# RockChip_RK3588 register map
Vendor: RockChip Electronics Co., Ltd.; Series: RK3588; File version: 0.1
Registers are 32-bit, read-write, no defined reset value unless marked. A register's access mark holds for its fields unless they carry their own. Offsets are from the block's base; [hi:lo] are bit positions; lines under a group give offsets from that group; {n}, {i} and the like mark numbered series; 'fields as' and 'values as' point back to an identical list.

## PMU (part 3 of 3)
Base 0xFD8D0000
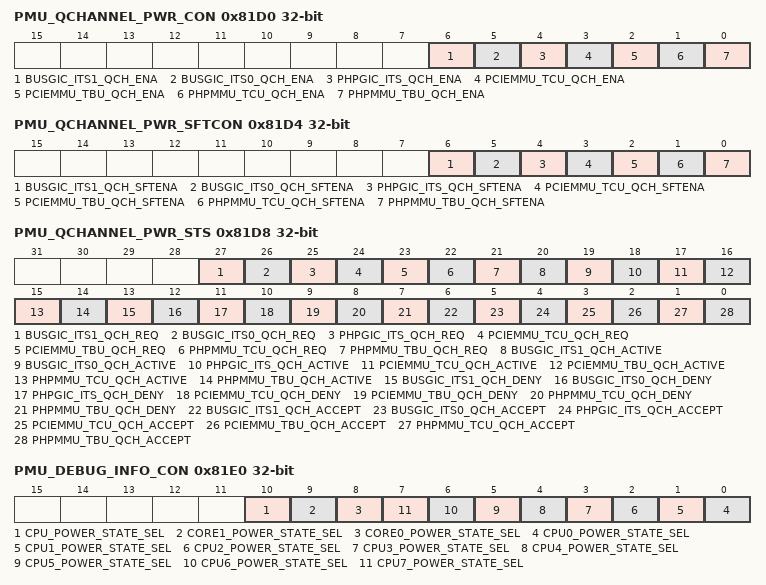
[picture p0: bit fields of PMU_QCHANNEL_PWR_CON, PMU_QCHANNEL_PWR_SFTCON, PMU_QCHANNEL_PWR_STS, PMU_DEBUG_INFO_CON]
0x81D0 PMU_QCHANNEL_PWR_CON — Q-Channel hardware power control register
  [all] fields
    0=DISABLE; 1=ENABLE
  [6] BUSGIC_ITS1_QCH_ENA — Enable BUSGIC-ITS1 Q-Channel power control by hardware.
  [5] BUSGIC_ITS0_QCH_ENA — Enable BUSGIC-ITS0 Q-Channel power control by hardware.
  [4] PHPGIC_ITS_QCH_ENA — Enable PHPGIC-ITS Q-Channel power control by hardware.
  [3] PCIEMMU_TCU_QCH_ENA — Enable PCIEMMU-TCU Q-Channel power control by hardware.
  [2] PCIEMMU_TBU_QCH_ENA — Enable PCIEMMU-TBU Q-Channel power control by hardware.
  [1] PHPMMU_TCU_QCH_ENA — Enable PHPMMU-TCU Q-Channel power control by hardware.
  [0] PHPMMU_TBU_QCH_ENA — Enable PHPMMU-TBU Q-Channel power control by hardware.
0x81D4 PMU_QCHANNEL_PWR_SFTCON — Q-Channel software power control register
  [all] fields
    0=DISABLE; 1=ENABLE
  [6] BUSGIC_ITS1_QCH_SFTENA — Enable BUSGIC-ITS1 Q-Channel power control by software.
  [5] BUSGIC_ITS0_QCH_SFTENA — Enable BUSGIC-ITS0 Q-Channel power control by software.
  [4] PHPGIC_ITS_QCH_SFTENA — Enable PHPGIC-ITS Q-Channel power control by software.
  [3] PCIEMMU_TCU_QCH_SFTENA — Enable PCIEMMU-TCU Q-Channel power control by software.
  [2] PCIEMMU_TBU_QCH_SFTENA — Enable PCIEMMU-TBU Q-Channel power control by software.
  [1] PHPMMU_TCU_QCH_SFTENA — Enable PHPMMU-TCU Q-Channel power control by software.
  [0] PHPMMU_TBU_QCH_SFTENA — Enable PHPMMU-TBU Q-Channel power control by software.
0x81D8 PMU_QCHANNEL_PWR_STS — Q-Channel power status register
  [27] BUSGIC_ITS1_QCH_REQ ro — Request status for BUSGIC-ITS1 Q-Channel power control.
    0=NOT_VALID; 1=VALID
  [26] BUSGIC_ITS0_QCH_REQ ro — Request status for BUSGIC-ITS0 Q-Channel power control.
    0=NOT_VALID; 1=VALID
  [25] PHPGIC_ITS_QCH_REQ ro — Request status for PHPGIC-ITS Q-Channel power control.
    0=NOT_VALID; 1=VALID
  [24] PCIEMMU_TCU_QCH_REQ ro — Request status for PCIEMMU-TCU Q-Channel power control.
    0=NOT_VALID; 1=VALID
  [23] PCIEMMU_TBU_QCH_REQ ro — Request status for PCIEMMU-TBU Q-Channel power control.
    0=NOT_VALID; 1=VALID
  [22] PHPMMU_TCU_QCH_REQ ro — Request status for PHPMMU-TCU Q-Channel power control.
    0=NOT_VALID; 1=VALID
  [21] PHPMMU_TBU_QCH_REQ ro — Request status for PHPMMU-TBU Q-Channel power control.
    0=NOT_VALID; 1=VALID
  [20] BUSGIC_ITS1_QCH_ACTIVE ro — Active status for PHPBUS-ITS1 Q-Channel power control.
    0=INACTIVE; 1=ACTIVE
  [19] BUSGIC_ITS0_QCH_ACTIVE ro — Active status for PHPBUS-ITS0 Q-Channel power control.
    0=INACTIVE; 1=ACTIVE
  [18] PHPGIC_ITS_QCH_ACTIVE ro — Active status for PHPGIC-ITS Q-Channel power control.
    0=INACTIVE; 1=ACTIVE
  [17] PCIEMMU_TCU_QCH_ACTIVE ro — Active status for PCIEMMU-TCU Q-Channel power control.
    0=INACTIVE; 1=ACTIVE
  [16] PCIEMMU_TBU_QCH_ACTIVE ro — Active status for PCIEMMU-TBU Q-Channel power control.
    0=INACTIVE; 1=ACTIVE
  [15] PHPMMU_TCU_QCH_ACTIVE ro — Active status for PHPMMU-TCU Q-Channel power control.
    0=INACTIVE; 1=ACTIVE
  [14] PHPMMU_TBU_QCH_ACTIVE ro — Active status for PHPMMU-TBU Q-Channel power control.
    0=INACTIVE; 1=ACTIVE
  [13] BUSGIC_ITS1_QCH_DENY ro — Deny status for PBUSGIC-ITS1 Q-Channel power control.
    0=NOT_DENY; 1=DENY
  [12] BUSGIC_ITS0_QCH_DENY ro — Deny status for BUSGIC-ITS0 Q-Channel power control.
    0=NOT_DENY; 1=DENY
  [11] PHPGIC_ITS_QCH_DENY ro — Deny status for PHPGIC-ITS Q-Channel power control.
    0=NOT_DENY; 1=DENY
  [10] PCIEMMU_TCU_QCH_DENY ro — Deny status for PCIEMMU-TCU Q-Channel power control.
    0=NOT_DENY; 1=DENY
  [9] PCIEMMU_TBU_QCH_DENY ro — Deny status for PCIEMMU-TBU Q-Channel power control.
    0=NOT_DENY; 1=DENY
  [8] PHPMMU_TCU_QCH_DENY ro — Deny status for PHPMMU-TCU Q-Channel power control.
    0=NOT_DENY; 1=DENY
  [7] PHPMMU_TBU_QCH_DENY ro — Deny status for PHPMMU-TBU Q-Channel power control.
    0=NOT_DENY; 1=DENY
  [6] BUSGIC_ITS1_QCH_ACCEPT ro — Accept status for BUSGIC-ITS1 Q-Channel power control.
    0=NOT ACCEPT; 1=ACCEPT
  [5] BUSGIC_ITS0_QCH_ACCEPT ro — Accept status for BUSGIC-ITS0 Q-Channel power control.
    0=NOT ACCEPT; 1=ACCEPT
  [4] PHPGIC_ITS_QCH_ACCEPT ro — Accept status for PHPGIC-ITS Q-Channel power control.
    0=NOT ACCEPT; 1=ACCEPT
  [3] PCIEMMU_TCU_QCH_ACCEPT ro — Accept status for PCIEMMU-TCU Q-Channel power control.
    0=NOT ACCEPT; 1=ACCEPT
  [2] PCIEMMU_TBU_QCH_ACCEPT ro — Accept status for PCIEMMU-TBU Q-Channel power control.
    0=NOT ACCEPT; 1=ACCEPT
  [1] PHPMMU_TCU_QCH_ACCEPT ro — Accept status for PHPMMU-TCU Q-Channel power control.
    0=NOT ACCEPT; 1=ACCEPT
  [0] PHPMMU_TBU_QCH_ACCEPT ro — Accept status for PHPMMU-TBU Q-Channel power control.
    0=NOT ACCEPT; 1=ACCEPT
0x81E0 PMU_DEBUG_INFO_CON — PMU debug information control register
  [all] fields
    0=NOT_SELECT; 1=SELECT
  [10] CPU_POWER_STATE_SEL — Select CPU power state as debug information output to IO.
  [9] CORE1_POWER_STATE_SEL — Select BIGCORE1 power state as debug information output to IO.
  [8] CORE0_POWER_STATE_SEL — Select BIGCORE0 power state as debug information output to IO.
  [n] CPU{n}_POWER_STATE_SEL (n=0..7) — Select CPU{n} power state as CPU power state.
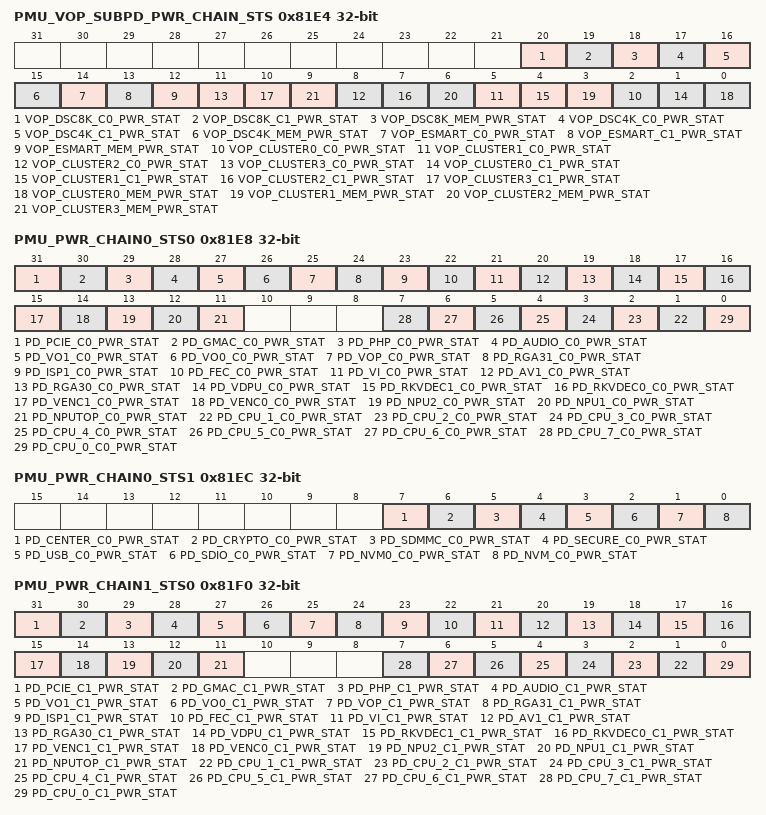
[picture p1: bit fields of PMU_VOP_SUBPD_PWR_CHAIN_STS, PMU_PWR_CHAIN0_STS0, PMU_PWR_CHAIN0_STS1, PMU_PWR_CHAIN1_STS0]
0x81E4 PMU_VOP_SUBPD_PWR_CHAIN_STS — VOP sub-domain power chain status register
  [20] VOP_DSC8K_C0_PWR_STAT ro — PD_VOPDSC8K power chain 0 power state.
    0=POWER_DOWN; 1=POWER_UP
  [19] VOP_DSC8K_C1_PWR_STAT ro — PD_VOPDSC8K power chain 1 power state.
    0=POWER_DOWN; 1=POWER_UP
  [18] VOP_DSC8K_MEM_PWR_STAT ro — PD_VOPDSC8K memory power state.
    0=POWER_UP; 1=POWER_DOWN
  [17] VOP_DSC4K_C0_PWR_STAT ro — PD_VOPDSC4K power chain 0 power state.
    0=POWER_DOWN; 1=POWER_UP
  [16] VOP_DSC4K_C1_PWR_STAT ro — PD_VOPDSC4K power chain 1 power state.
    0=POWER_DOWN; 1=POWER_UP
  [15] VOP_DSC4K_MEM_PWR_STAT ro — PD_VOPDSC4K memory power state.
    0=POWER_UP; 1=POWER_DOWN
  [14] VOP_ESMART_C0_PWR_STAT ro — PD_VOPESMART power chain 0 power state.
    0=POWER_DOWN; 1=POWER_UP
  [13] VOP_ESMART_C1_PWR_STAT ro — PD_VOPESMART power chain 1 power state.
    0=POWER_DOWN; 1=POWER_UP
  [12] VOP_ESMART_MEM_PWR_STAT ro — PD_VOPESMART memory power state.
    0=POWER_UP; 1=POWER_DOWN
  [3n+2] VOP_CLUSTER{n}_C0_PWR_STAT ro (n=0..3) — PD_VOPCLUSTER{n} power chain 0 power state.
    0=POWER_DOWN; 1=POWER_UP
  [3n+1] VOP_CLUSTER{n}_C1_PWR_STAT ro (n=0..3) — PD_VOPCLUSTER{n} power chain 1 power state.
    0=POWER_DOWN; 1=POWER_UP
  [3n] VOP_CLUSTER{n}_MEM_PWR_STAT ro (n=0..3) — PD_VOPCLUSTER{n} memory power state.
    0=POWER_UP; 1=POWER_DOWN
0x81E8 PMU_PWR_CHAIN0_STS0 — Power domain power chain 0 status register 0
  [31] PD_PCIE_C0_PWR_STAT ro — The power state of PD_PCIE power chain 0.
    0=POWER_DOWN; 1=POWER_UP
  [30] PD_GMAC_C0_PWR_STAT ro — The power state of PD_GMAC power chain 0.
    0=POWER_DOWN; 1=POWER_UP
  [29] PD_PHP_C0_PWR_STAT ro — The power state of PD_PHP power chain 0.
    0=POWER_DOWN; 1=POWER_UP
  [28] PD_AUDIO_C0_PWR_STAT ro — The power state of PD_AUDIO power chain 0.
    0=POWER_DOWN; 1=POWER_UP
  [27] PD_VO1_C0_PWR_STAT ro — The power state of PD_VO1 power chain 0.
    0=POWER_DOWN; 1=POWER_UP
  [26] PD_VO0_C0_PWR_STAT ro — The power state of PD_VO0 power chain 0.
    0=POWER_DOWN; 1=POWER_UP
  [25] PD_VOP_C0_PWR_STAT ro — The power state of PD_VOP power chain 0.
    0=POWER_DOWN; 1=POWER_UP
  [24] PD_RGA31_C0_PWR_STAT ro — The power state of PD_RGA31 power chain 0.
    0=POWER_DOWN; 1=POWER_UP
  [23] PD_ISP1_C0_PWR_STAT ro — The power state of PD_ISP1 power chain 0.
    0=POWER_DOWN; 1=POWER_UP
  [22] PD_FEC_C0_PWR_STAT ro — The power state of PD_FEC power chain 0.
    0=POWER_DOWN; 1=POWER_UP
  [21] PD_VI_C0_PWR_STAT ro — The power state of PD_VI power chain 0.
    0=POWER_DOWN; 1=POWER_UP
  [20] PD_AV1_C0_PWR_STAT ro — The power state of PD_AV1 power chain 0.
    0=POWER_DOWN; 1=POWER_UP
  [19] PD_RGA30_C0_PWR_STAT ro — The power state of PD_RGA30.
    0=POWER_DOWN; 1=POWER_UP
  [18] PD_VDPU_C0_PWR_STAT ro — The power state of PD_VDPU power chain 0.
    0=POWER_DOWN; 1=POWER_UP
  [17] PD_RKVDEC1_C0_PWR_STAT ro — The power state of PD_RKVDEC1 power chain 0.
    0=POWER_DOWN; 1=POWER_UP
  [16] PD_RKVDEC0_C0_PWR_STAT ro — The power state of PD_RKVDEC0 power chain 0.
    0=POWER_DOWN; 1=POWER_UP
  [15] PD_VENC1_C0_PWR_STAT ro — The power state of PD_VENC1 power chain 0.
    0=POWER_DOWN; 1=POWER_UP
  [14] PD_VENC0_C0_PWR_STAT ro — The power state of PD_VENC0 power chain 0.
    0=POWER_DOWN; 1=POWER_UP
  [13] PD_NPU2_C0_PWR_STAT ro — The power state of PD_NPU2 power chain 0.
    0=POWER_DOWN; 1=POWER_UP
  [12] PD_NPU1_C0_PWR_STAT ro — The power state of PD_NPU1 power chain 0.
    0=POWER_DOWN; 1=POWER_UP
  [11] PD_NPUTOP_C0_PWR_STAT ro — The power state of PD_NPUTOP power chain 0.
    0=POWER_DOWN; 1=POWER_UP
  [n] PD_CPU_{n}_C0_PWR_STAT ro (n=1..7) — The power state of PD_CPU_{n} power chain 0.
    0=POWER_DOWN; 1=POWER_UP
  [0] PD_CPU_0_C0_PWR_STAT ro — The power state of PD_CPU_0 power chain 0.
    0=POWER_DOWN; 1=POWER UP
0x81EC PMU_PWR_CHAIN0_STS1 — Power domain power chain 0 status register 1
  [7] PD_CENTER_C0_PWR_STAT ro — The power state of PD_CENTER power chain 0.
    0=POWER_DOWN; 1=POWER_UP
  [6] PD_CRYPTO_C0_PWR_STAT ro — The power state of PD_CRYPTO power chain 0.
    0=POWER_DOWN; 1=POWER_UP
  [5] PD_SDMMC_C0_PWR_STAT ro — The power state of PD_SDMMC power chain 0.
    0=POWER_DOWN; 1=POWER_UP
  [4] PD_SECURE_C0_PWR_STAT ro — The power state of PD_SECURE power chain 0.
    0=POWER_DOWN; 1=POWER_UP
  [3] PD_USB_C0_PWR_STAT ro — The power state of PD_USB power chain 0.
    0=POWER_DOWN; 1=POWER_UP
  [2] PD_SDIO_C0_PWR_STAT ro — The power state of PD_SDIO power chain 0.
    0=POWER_DOWN; 1=POWER_UP
  [1] PD_NVM0_C0_PWR_STAT ro — The power state of PD_NVM0 power chain 0.
    0=POWER_DOWN; 1=POWER_UP
  [0] PD_NVM_C0_PWR_STAT ro — The power state of PD_NVM power chain 0.
    0=POWER_DOWN; 1=POWER UP
0x81F0 PMU_PWR_CHAIN1_STS0 — Power domain power chain 1 status register 0
  [31] PD_PCIE_C1_PWR_STAT ro — The power state of PD_PCIE power chain 1.
    0=POWER_DOWN; 1=POWER_UP
  [30] PD_GMAC_C1_PWR_STAT ro — The power state of PD_GMAC power chain 1.
    0=POWER_DOWN; 1=POWER_UP
  [29] PD_PHP_C1_PWR_STAT ro — The power state of PD_PHP power chain 1.
    0=POWER_DOWN; 1=POWER_UP
  [28] PD_AUDIO_C1_PWR_STAT ro — The power state of PD_AUDIO power chain 1.
    0=POWER_DOWN; 1=POWER_UP
  [27] PD_VO1_C1_PWR_STAT ro — The power state of PD_VO1 power chain 1.
    0=POWER_DOWN; 1=POWER_UP
  [26] PD_VO0_C1_PWR_STAT ro — The power state of PD_VO0 power chain 1.
    0=POWER_DOWN; 1=POWER_UP
  [25] PD_VOP_C1_PWR_STAT ro — The power state of PD_VOP power chain 1.
    0=POWER_DOWN; 1=POWER_UP
  [24] PD_RGA31_C1_PWR_STAT ro — The power state of PD_RGA31 power chain 1.
    0=POWER_DOWN; 1=POWER_UP
  [23] PD_ISP1_C1_PWR_STAT ro — The power state of PD_ISP1 power chain 1.
    0=POWER_DOWN; 1=POWER_UP
  [22] PD_FEC_C1_PWR_STAT ro — The power state of PD_FEC power chain 1.
    0=POWER_DOWN; 1=POWER_UP
  [21] PD_VI_C1_PWR_STAT ro — The power state of PD_VI power chain 1.
    0=POWER_DOWN; 1=POWER_UP
  [20] PD_AV1_C1_PWR_STAT ro — The power state of PD_AV1 power chain 1.
    0=POWER_DOWN; 1=POWER_UP
  [19] PD_RGA30_C1_PWR_STAT ro — The power state of PD_RGA30.
    0=POWER_DOWN; 1=POWER_UP
  [18] PD_VDPU_C1_PWR_STAT ro — The power state of PD_VDPU power chain 1.
    0=POWER_DOWN; 1=POWER_UP
  [17] PD_RKVDEC1_C1_PWR_STAT ro — The power state of PD_RKVDEC1 power chain 1.
    0=POWER_DOWN; 1=POWER_UP
  [16] PD_RKVDEC0_C1_PWR_STAT ro — The power state of PD_RKVDEC0 power chain 1.
    0=POWER_DOWN; 1=POWER_UP
  [15] PD_VENC1_C1_PWR_STAT ro — The power state of PD_VENC1 power chain 1.
    0=POWER_DOWN; 1=POWER_UP
  [14] PD_VENC0_C1_PWR_STAT ro — The power state of PD_VENC0 power chain 1.
    0=POWER_DOWN; 1=POWER_UP
  [13] PD_NPU2_C1_PWR_STAT ro — The power state of PD_NPU2 power chain 1.
    0=POWER_DOWN; 1=POWER_UP
  [12] PD_NPU1_C1_PWR_STAT ro — The power state of PD_NPU1 power chain 1.
    0=POWER_DOWN; 1=POWER_UP
  [11] PD_NPUTOP_C1_PWR_STAT ro — The power state of PD_NPUTOP power chain 1.
    0=POWER_DOWN; 1=POWER_UP
  [n] PD_CPU_{n}_C1_PWR_STAT ro (n=1..7) — The power state of PD_CPU_{n} power chain 1.
    0=POWER_DOWN; 1=POWER_UP
  [0] PD_CPU_0_C1_PWR_STAT ro — The power state of PD_CPU_0 power chain 1.
    0=POWER_DOWN; 1=POWER UP
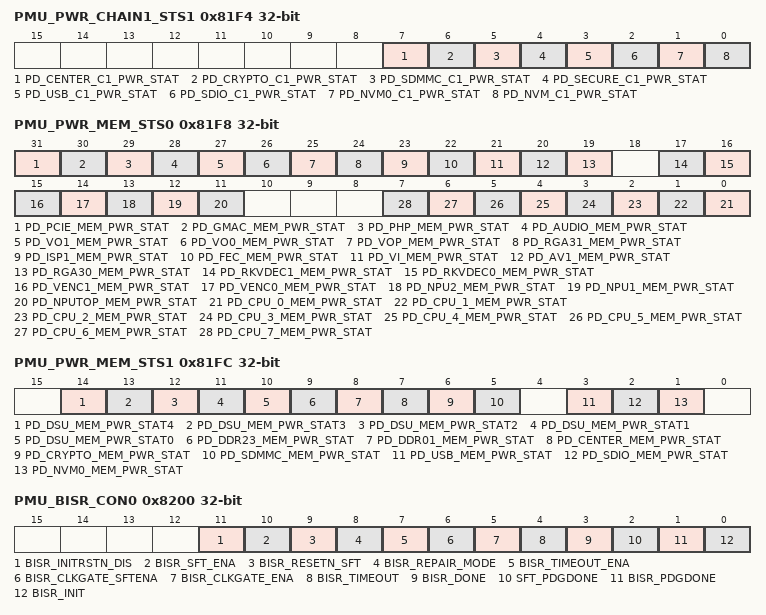
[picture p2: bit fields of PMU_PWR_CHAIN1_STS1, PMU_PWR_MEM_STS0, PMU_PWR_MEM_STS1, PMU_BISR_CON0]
0x81F4 PMU_PWR_CHAIN1_STS1 — Power domain power chain 1 status register 1
  [7] PD_CENTER_C1_PWR_STAT ro — The power state of PD_CENTER power chain 1.
    0=POWER_DOWN; 1=POWER_UP
  [6] PD_CRYPTO_C1_PWR_STAT ro — The power state of PD_CRYPTO power chain 1.
    0=POWER_DOWN; 1=POWER_UP
  [5] PD_SDMMC_C1_PWR_STAT ro — The power state of PD_SDMMC power chain 1.
    0=POWER_DOWN; 1=POWER_UP
  [4] PD_SECURE_C1_PWR_STAT ro — The power state of PD_SECURE power chain 1.
    0=POWER_DOWN; 1=POWER_UP
  [3] PD_USB_C1_PWR_STAT ro — The power state of PD_USB power chain 1.
    0=POWER_DOWN; 1=POWER_UP
  [2] PD_SDIO_C1_PWR_STAT ro — The power state of PD_SDIO power chain 1.
    0=POWER_DOWN; 1=POWER_UP
  [1] PD_NVM0_C1_PWR_STAT ro — The power state of PD_NVM0 power chain 1.
    0=POWER_DOWN; 1=POWER_UP
  [0] PD_NVM_C1_PWR_STAT ro — The power state of PD_NVM power chain 1.
    0=POWER_DOWN; 1=POWER UP
0x81F8 PMU_PWR_MEM_STS0 — Power domain memory power status register 0
  [all] fields
    0=POWER_UP; 1=POWER_DOWN
  [31] PD_PCIE_MEM_PWR_STAT ro — The power state of PD_PCIE memory.
  [30] PD_GMAC_MEM_PWR_STAT ro — The power state of PD_GMAC memory.
  [29] PD_PHP_MEM_PWR_STAT ro — The power state of PD_PHP memory.
  [28] PD_AUDIO_MEM_PWR_STAT ro — The power state of PD_AUDIO memory.
  [27] PD_VO1_MEM_PWR_STAT ro — The power state of PD_VO1 memory.
  [26] PD_VO0_MEM_PWR_STAT ro — The power state of PD_VO0 memory.
  [25] PD_VOP_MEM_PWR_STAT ro — The power state of PD_VOP memory.
  [24] PD_RGA31_MEM_PWR_STAT ro — The power state of PD_RGA31 memory.
  [23] PD_ISP1_MEM_PWR_STAT ro — The power state of PD_ISP1 memory.
  [22] PD_FEC_MEM_PWR_STAT ro — The power state of PD_FEC memory.
  [21] PD_VI_MEM_PWR_STAT ro — The power state of PD_VI memory.
  [20] PD_AV1_MEM_PWR_STAT ro — The power state of PD_AV1 memory.
  [19] PD_RGA30_MEM_PWR_STAT ro — The power state of PD_RGA30 memory.
  [17] PD_RKVDEC1_MEM_PWR_STAT ro — The power state of PD_RKVDEC1 memory.
  [16] PD_RKVDEC0_MEM_PWR_STAT ro — The power state of PD_RKVDEC0 memory.
  [15] PD_VENC1_MEM_PWR_STAT ro — The power state of PD_VENC1 memory.
  [14] PD_VENC0_MEM_PWR_STAT ro — The power state of PD_VENC0 memory.
  [13] PD_NPU2_MEM_PWR_STAT ro — The power state of PD_NPU2 memory.
  [12] PD_NPU1_MEM_PWR_STAT ro — The power state of PD_NPU1 memory.
  [11] PD_NPUTOP_MEM_PWR_STAT ro — The power state of PD_NPUTOP memory.
  [n] PD_CPU_{n}_MEM_PWR_STAT ro (n=0..7) — The power state of PD_CPU_{n} memory.
0x81FC PMU_PWR_MEM_STS1 — Power domain memory power status register 1
  [all] fields
    0=POWER_UP; 1=POWER_DOWN
  [14] PD_DSU_MEM_PWR_STAT4 ro — used to indicate other memory power state.
  [13] PD_DSU_MEM_PWR_STAT3 ro — used to indicate "L3 Tag ways 8~11, L3 Data portion 1 RAMs" memory power state.
  [12] PD_DSU_MEM_PWR_STAT2 ro — used to indicate "L3 Tag ways 4~7" memory power state.
  [11] PD_DSU_MEM_PWR_STAT1 ro — used to indicate "L3 Tag ways 0~3, L3 Data portion 0, and L3 Victim RAMs" memory state.
  [10] PD_DSU_MEM_PWR_STAT0 ro — used to indicate "Snoop filter and LTDB RAMs" memory power state.
  [9] PD_DDR23_MEM_PWR_STAT ro — The power state of VD_DDR23 memory.
  [8] PD_DDR01_MEM_PWR_STAT ro — The power state of VD_DDR01 memory.
  [7] PD_CENTER_MEM_PWR_STAT ro — The power state of PD_CENTER memory.
  [6] PD_CRYPTO_MEM_PWR_STAT ro — The power state of PD_CRYPTO memory.
  [5] PD_SDMMC_MEM_PWR_STAT ro — The power state of PD_SDMMC memory.
  [3] PD_USB_MEM_PWR_STAT ro — The power state of PD_USB memory.
  [2] PD_SDIO_MEM_PWR_STAT ro — The power state of PD_SDIO memory.
  [1] PD_NVM0_MEM_PWR_STAT ro — The power state of PD_NVM0 memory.
0x8200 PMU_BISR_CON0 — Memory repair control register 0
  [11] BISR_INITRSTN_DIS — Disable initial reset for memory repair logic.
    0=ENABLE; 1=DISABLE
  [10] BISR_SFT_ENA — Enable memory repair control by software.
    0=DISABLE; 1=ENABLE
  [9] BISR_RESETN_SFT — Generate bisr_resetN by software.
  [8] BISR_REPAIR_MODE — Memory repair mode.
    0=SERIAL (Serial repair mode. In this mode, memory repair will start after power domain is power up, not need to wait for other domain power up. If multi domains are power up at the same time, the repair is executed according to the repair group order.); 1=PARALLEL (Parallel repair mode. In this mode, memory repair will not start until all specified power domains are power up.)
  [7] BISR_TIMEOUT_ENA — Enable memory repair timeout counter.
    0=DISABLE; 1=ENABLE
  [6] BISR_CLKGATE_SFTENA — Enable memory repair clock gating by software. If asserted, memory repair clock is gated.
    0=DISABLE; 1=ENABLE
  [5] BISR_CLKGATE_ENA — Enable memory repair auto clock gating by hardware. If asserted, memory repair clock is auto gated when memory repair is idle.
    0=DISABLE; 1=ENABLE
  [4] BISR_TIMEOUT — PDGDone come from bisr_timeout, controlled by hardware. Only one bit can be set to 1 at a time.
  [3] BISR_DONE — PDGDone come from bisr_Done, controlled by hardware. Only one bit can be set to 1 at a time.
  [2] SFT_PDGDONE — PDGDone come from sft_PDGDone (pd_xx_pdgdone_sftena), controlled by software. Only one bit can be set to 1 at a time.
  [1] BISR_PDGDONE — PDGDone come from bisr_PDGDone, controlled by hardware. Only one bit can be set to 1 at a time.
  [0] BISR_INIT — Enable memory repair initialization. When asserted, the chip will startup memory repair for memory of power on if external memory repair information is ready. It should be set to 0 if chip is reset by software.
    0=DISABLE; 1=ENABLE
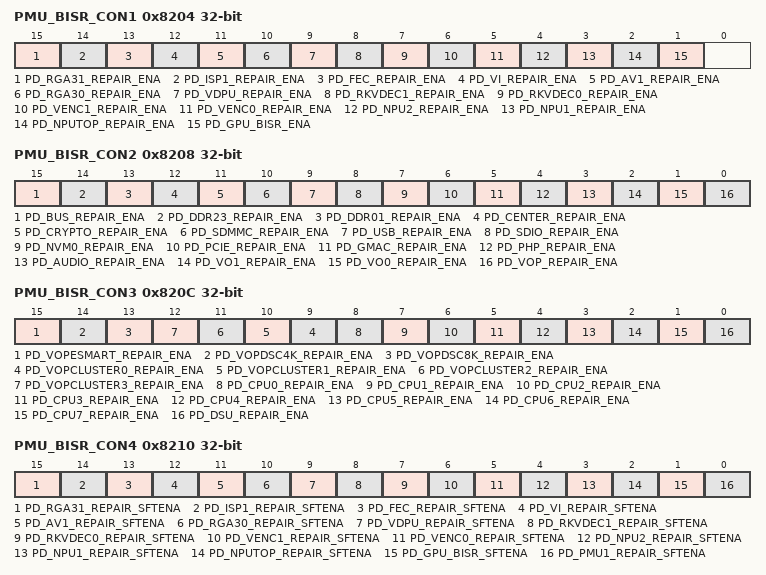
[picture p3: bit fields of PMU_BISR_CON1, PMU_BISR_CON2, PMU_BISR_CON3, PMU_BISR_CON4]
0x8204 PMU_BISR_CON1 — Memory repair control register 1
  [all] fields
    0=DISABLE; 1=ENABLE
  [15] PD_RGA31_REPAIR_ENA — Enable memory repair for PD_RGA31 by hardware.
  [14] PD_ISP1_REPAIR_ENA — Enable memory repair for PD_ISP1 by hardware.
  [13] PD_FEC_REPAIR_ENA — Enable memory repair for PD_FEC by hardware.
  [12] PD_VI_REPAIR_ENA — Enable memory repair for PD_VI by hardware.
  [11] PD_AV1_REPAIR_ENA — Enable memory repair for PD_AV1 by hardware.
  [10] PD_RGA30_REPAIR_ENA — Enable memory repair for PD_RGA30 by hardware.
  [9] PD_VDPU_REPAIR_ENA — Enable memory repair for PD_VDPU by hardware.
  [8] PD_RKVDEC1_REPAIR_ENA — Enable memory repair for PD_RKVDEC1 by hardware.
  [7] PD_RKVDEC0_REPAIR_ENA — Enable memory repair for PD_RKVDEC0 by hardware.
  [6] PD_VENC1_REPAIR_ENA — Enable memory repair for PD_VENC1 by hardware.
  [5] PD_VENC0_REPAIR_ENA — Enable memory repair for PD_VENC0 by hardware.
  [4] PD_NPU2_REPAIR_ENA — Enable memory repair for PD_NPU2 by hardware.
  [3] PD_NPU1_REPAIR_ENA — Enable memory repair for PD_NPU1 by hardware.
  [2] PD_NPUTOP_REPAIR_ENA — Enable memory repair for PD_NPUTOP by hardware.
  [1] PD_GPU_BISR_ENA — Enable memory repair for VD_GPU by hardware.
0x8208 PMU_BISR_CON2 — Memory repair control register 2
  [all] fields
    0=DISABLE; 1=ENABLE
  [15] PD_BUS_REPAIR_ENA — Enable memory repair for PD_BUS by hardware.
  [14] PD_DDR23_REPAIR_ENA — Enable memory repair for VD_DDR23 by hardware.
  [13] PD_DDR01_REPAIR_ENA — Enable memory repair for VD_DDR01 by hardware.
  [12] PD_CENTER_REPAIR_ENA — Enable memory repair for PD_CENTER by hardware.
  [11] PD_CRYPTO_REPAIR_ENA — Enable memory repair for PD_CRYPTO by hardware.
  [10] PD_SDMMC_REPAIR_ENA — Enable memory repair for PD_SDMMC by hardware.
  [9] PD_USB_REPAIR_ENA — Enable memory repair for PD_USB by hardware.
  [8] PD_SDIO_REPAIR_ENA — Enable memory repair for PD_SDIO by hardware.
  [7] PD_NVM0_REPAIR_ENA — Enable memory repair for PD_NVM0 by hardware.
  [6] PD_PCIE_REPAIR_ENA — Enable memory repair for PD_PCIE by hardware.
  [5] PD_GMAC_REPAIR_ENA — Enable memory repair for PD_GMAC by hardware.
  [4] PD_PHP_REPAIR_ENA — Enable memory repair for PD_PHP by hardware.
  [3] PD_AUDIO_REPAIR_ENA — Enable memory repair for PD_AUDIO by hardware.
  [2] PD_VO1_REPAIR_ENA — Enable memory repair for PD_VO1 by hardware.
  [1] PD_VO0_REPAIR_ENA — Enable memory repair for PD_VO0 by hardware.
  [0] PD_VOP_REPAIR_ENA — Enable memory repair for PD_VOP by hardware.
0x820C PMU_BISR_CON3 — Memory repair control register 3
  [all] fields
    0=DISABLE; 1=ENABLE
  [15] PD_VOPESMART_REPAIR_ENA — Enable memory repair for PD_VOPESMART by hardware.
  [14] PD_VOPDSC4K_REPAIR_ENA — Enable memory repair for PD_VOPDSC4K by hardware.
  [13] PD_VOPDSC8K_REPAIR_ENA — Enable memory repair for PD_VOPDSC8K by hardware.
  [n+9] PD_VOPCLUSTER{n}_REPAIR_ENA (n=0..3) — Enable memory repair for PD_VOPCLUSTER{n} by hardware.
  [8-n] PD_CPU{n}_REPAIR_ENA (n=0..7) — Enable memory repair for PD_CPU{n} by hardware.
  [0] PD_DSU_REPAIR_ENA — Enable memory repair for PD_DSU by hardware.
0x8210 PMU_BISR_CON4 — Memory repair control register 4
  [all] fields
    0=DISABLE; 1=ENABLE
  [15] PD_RGA31_REPAIR_SFTENA — Enable memory repair for PD_RGA31 by software.
  [14] PD_ISP1_REPAIR_SFTENA — Enable memory repair for PD_ISP1 by software.
  [13] PD_FEC_REPAIR_SFTENA — Enable memory repair for PD_FEC by software.
  [12] PD_VI_REPAIR_SFTENA — Enable memory repair for PD_VI by software.
  [11] PD_AV1_REPAIR_SFTENA — Enable memory repair for PD_AV1 by software.
  [10] PD_RGA30_REPAIR_SFTENA — Enable memory repair for PD_RGA30 by software.
  [9] PD_VDPU_REPAIR_SFTENA — Enable memory repair for PD_VDPU by software.
  [8] PD_RKVDEC1_REPAIR_SFTENA — Enable memory repair for PD_RKVDEC1 by software.
  [7] PD_RKVDEC0_REPAIR_SFTENA — Enable memory repair for PD_RKVDEC0 by software.
  [6] PD_VENC1_REPAIR_SFTENA — Enable memory repair for PD_VENC1 by software.
  [5] PD_VENC0_REPAIR_SFTENA — Enable memory repair for PD_VENC0 by software.
  [4] PD_NPU2_REPAIR_SFTENA — Enable memory repair for PD_NPU2 by software.
  [3] PD_NPU1_REPAIR_SFTENA — Enable memory repair for PD_NPU1 by software.
  [2] PD_NPUTOP_REPAIR_SFTENA — Enable memory repair for PD_NPUTOP by software.
  [1] PD_GPU_BISR_SFTENA — Enable memory repair for VD_GPU by software.
  [0] PD_PMU1_REPAIR_SFTENA — Enable memory repair for PD_PMU1 by software.
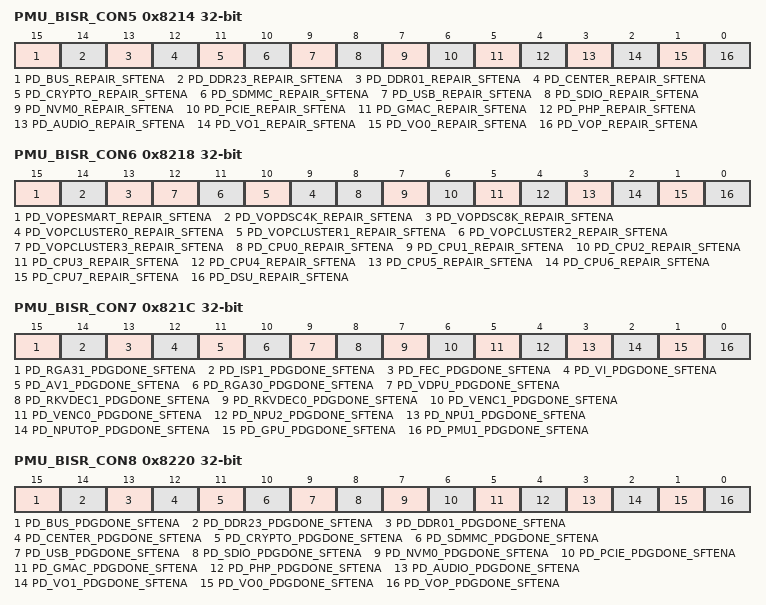
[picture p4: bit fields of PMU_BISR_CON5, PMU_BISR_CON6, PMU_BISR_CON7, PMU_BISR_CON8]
0x8214 PMU_BISR_CON5 — Memory repair control register 5
  [all] fields
    0=DISABLE; 1=ENABLE
  [15] PD_BUS_REPAIR_SFTENA — Enable memory repair for PD_BUS by software.
  [14] PD_DDR23_REPAIR_SFTENA — Enable memory repair for VD_DDR23 by software.
  [13] PD_DDR01_REPAIR_SFTENA — Enable memory repair for VD_DDR01 by software.
  [12] PD_CENTER_REPAIR_SFTENA — Enable memory repair for PD_CENTER by software.
  [11] PD_CRYPTO_REPAIR_SFTENA — Enable memory repair for PD_CRYPTO by software.
  [10] PD_SDMMC_REPAIR_SFTENA — Enable memory repair for PD_SDMMC by software.
  [9] PD_USB_REPAIR_SFTENA — Enable memory repair for PD_USB by software.
  [8] PD_SDIO_REPAIR_SFTENA — Enable memory repair for PD_SDIO by software.
  [7] PD_NVM0_REPAIR_SFTENA — Enable memory repair for PD_NVM0 by software.
  [6] PD_PCIE_REPAIR_SFTENA — Enable memory repair for PD_PCIE by software.
  [5] PD_GMAC_REPAIR_SFTENA — Enable memory repair for PD_GMAC by software.
  [4] PD_PHP_REPAIR_SFTENA — Enable memory repair for PD_PHP by software.
  [3] PD_AUDIO_REPAIR_SFTENA — Enable memory repair for PD_AUDIO by software.
  [2] PD_VO1_REPAIR_SFTENA — Enable memory repair for PD_VO1 by software.
  [1] PD_VO0_REPAIR_SFTENA — Enable memory repair for PD_VO0 by software.
  [0] PD_VOP_REPAIR_SFTENA — Enable memory repair for PD_VOP by software.
0x8218 PMU_BISR_CON6 — Memory repair control register 6
  [all] fields
    0=DISABLE; 1=ENABLE
  [15] PD_VOPESMART_REPAIR_SFTENA — Enable memory repair for PD_VOPESMART by software.
  [14] PD_VOPDSC4K_REPAIR_SFTENA — Enable memory repair for PD_VOPDSC4K by software.
  [13] PD_VOPDSC8K_REPAIR_SFTENA — Enable memory repair for PD_VOPDSC8K by software.
  [n+9] PD_VOPCLUSTER{n}_REPAIR_SFTENA (n=0..3) — Enable memory repair for PD_VOPCLUSTER{n} by software.
  [8-n] PD_CPU{n}_REPAIR_SFTENA (n=0..7) — Enable memory repair for PD_CPU{n} by software.
  [0] PD_DSU_REPAIR_SFTENA — Enable memory repair for PD_DSU by software.
0x821C PMU_BISR_CON7 — Memory repair control register 7
  [all] fields
    0=INACTIVE; 1=ACTIVE
  [15] PD_RGA31_PDGDONE_SFTENA — Configure repair done for PD_RGA31 by software.
  [14] PD_ISP1_PDGDONE_SFTENA — Configure repair done for PD_ISP1 by software.
  [13] PD_FEC_PDGDONE_SFTENA — Configure repair done for PD_FEC by software.
  [12] PD_VI_PDGDONE_SFTENA — Configure repair done for PD_VI by software.
  [11] PD_AV1_PDGDONE_SFTENA — Configure repair done for PD_AV1 by software.
  [10] PD_RGA30_PDGDONE_SFTENA — Configure repair done for PD_RGA30 by software.
  [9] PD_VDPU_PDGDONE_SFTENA — Configure repair done for PD_VDPU by software.
  [8] PD_RKVDEC1_PDGDONE_SFTENA — Configure repair done for PD_RKVDEC1 by software.
  [7] PD_RKVDEC0_PDGDONE_SFTENA — Configure repair done for PD_RKVDEC0 by software.
  [6] PD_VENC1_PDGDONE_SFTENA — Configure repair done for PD_VENC1 by software.
  [5] PD_VENC0_PDGDONE_SFTENA — Configure repair done for PD_VENC0 by software.
  [4] PD_NPU2_PDGDONE_SFTENA — Configure repair done for PD_NPU2 by software.
  [3] PD_NPU1_PDGDONE_SFTENA — Configure repair done for PD_NPU1 by software.
  [2] PD_NPUTOP_PDGDONE_SFTENA — Configure repair done for PD_NPUTOP by software.
  [1] PD_GPU_PDGDONE_SFTENA — Configure repair done for VD_GPU by software.
  [0] PD_PMU1_PDGDONE_SFTENA — Configure repair done for PD_PMU1 by software.
0x8220 PMU_BISR_CON8 — Memory repair control register 8
  [all] fields
    0=INACTIVE; 1=ACTIVE
  [15] PD_BUS_PDGDONE_SFTENA — Configure repair done for PD_BUS by software.
  [14] PD_DDR23_PDGDONE_SFTENA — Configure repair done for VD_DDR23 by software.
  [13] PD_DDR01_PDGDONE_SFTENA — Configure repair done for VD_DDR01 by software.
  [12] PD_CENTER_PDGDONE_SFTENA — Configure repair done for PD_CENTER by software.
  [11] PD_CRYPTO_PDGDONE_SFTENA — Configure repair done for PD_CRYPTO by software.
  [10] PD_SDMMC_PDGDONE_SFTENA — Configure repair done for PD_SDMMC by software.
  [9] PD_USB_PDGDONE_SFTENA — Configure repair done for PD_USB by software.
  [8] PD_SDIO_PDGDONE_SFTENA — Configure repair done for PD_SDIO by software.
  [7] PD_NVM0_PDGDONE_SFTENA — Configure repair done for PD_NVM0 by software.
  [6] PD_PCIE_PDGDONE_SFTENA — Configure repair done for PD_PCIE by software.
  [5] PD_GMAC_PDGDONE_SFTENA — Configure repair done for PD_GMAC by software.
  [4] PD_PHP_PDGDONE_SFTENA — Configure repair done for PD_PHP by software.
  [3] PD_AUDIO_PDGDONE_SFTENA — Configure repair done for PD_AUDIO by software.
  [2] PD_VO1_PDGDONE_SFTENA — Configure repair done for PD_VO1 by software.
  [1] PD_VO0_PDGDONE_SFTENA — Configure repair done for PD_VO0 by software.
  [0] PD_VOP_PDGDONE_SFTENA — Active repair PD_VOP by software.
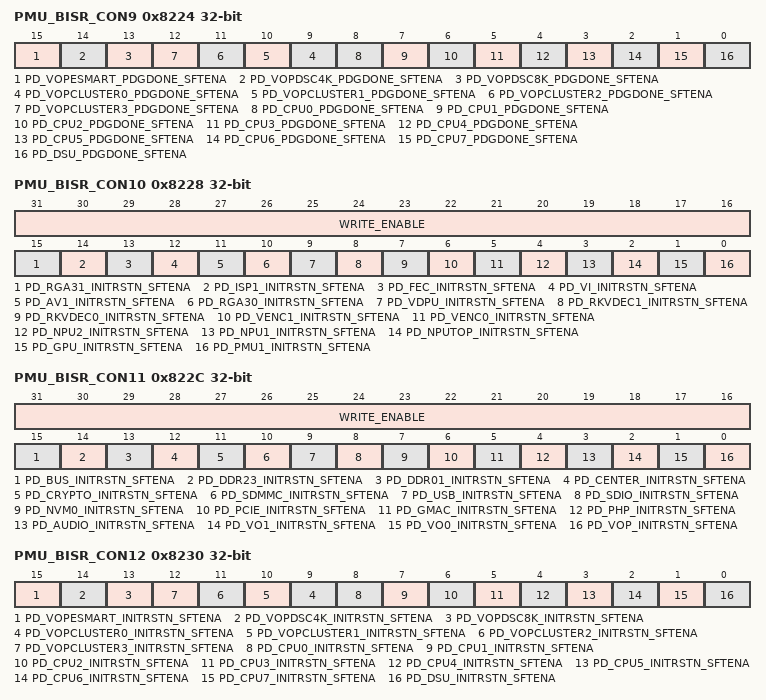
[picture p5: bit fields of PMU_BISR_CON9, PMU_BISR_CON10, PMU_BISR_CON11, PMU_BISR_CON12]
0x8224 PMU_BISR_CON9 — Memory repair control register 9
  [all] fields
    0=INACTIVE; 1=ACTIVE
  [15] PD_VOPESMART_PDGDONE_SFTENA — Configure repair done for PD_VOPESMART by software.
  [14] PD_VOPDSC4K_PDGDONE_SFTENA — Configure repair done for PD_VOPDSC4K by software.
  [13] PD_VOPDSC8K_PDGDONE_SFTENA — Configure repair done for PD_VOPDSC8K by software.
  [n+9] PD_VOPCLUSTER{n}_PDGDONE_SFTENA (n=0..3) — Configure repair done for PD_VOPCLUSTER{n} by software.
  [8-n] PD_CPU{n}_PDGDONE_SFTENA (n=0..7) — Configure repair done for PD_CPU{n} by software.
  [0] PD_DSU_PDGDONE_SFTENA — Configure repair done for PD_DSU by software.
0x8228 PMU_BISR_CON10 — Memory repair control register 10
  [31:16] WRITE_ENABLE wo — Write Inactive for lower 16 bits, each bit is individual.
    0=ACTIVE (Write access Active); 1=INACTIVE (Write access Inactive)
  [15] PD_RGA31_INITRSTN_SFTENA — Configure initial reset for PD_RGA31 by software.
    0=ACTIVE; 1=INACTIVE
  [14] PD_ISP1_INITRSTN_SFTENA — Configure initial reset for PD_ISP1 by software.
    0=ACTIVE; 1=INACTIVE
  [13] PD_FEC_INITRSTN_SFTENA — Configure initial reset for PD_FEC by software.
    0=ACTIVE; 1=INACTIVE
  [12] PD_VI_INITRSTN_SFTENA — Configure initial reset for PD_VI by software.
    0=ACTIVE; 1=INACTIVE
  [11] PD_AV1_INITRSTN_SFTENA — Configure initial reset for PD_AV1 by software.
    0=ACTIVE; 1=INACTIVE
  [10] PD_RGA30_INITRSTN_SFTENA — Configure initial reset for PD_RGA30 by software.
    0=ACTIVE; 1=INACTIVE
  [9] PD_VDPU_INITRSTN_SFTENA — Configure initial reset for PD_VDPU by software.
    0=ACTIVE; 1=INACTIVE
  [8] PD_RKVDEC1_INITRSTN_SFTENA — Configure initial reset for PD_RKVDEC1 by software.
    0=ACTIVE; 1=INACTIVE
  [7] PD_RKVDEC0_INITRSTN_SFTENA — Configure initial reset for PD_RKVDEC0 by software.
    0=ACTIVE; 1=INACTIVE
  [6] PD_VENC1_INITRSTN_SFTENA — Configure initial reset for PD_VENC1 by software.
    0=ACTIVE; 1=INACTIVE
  [5] PD_VENC0_INITRSTN_SFTENA — Configure initial reset for PD_VENC0 by software.
    0=ACTIVE; 1=INACTIVE
  [4] PD_NPU2_INITRSTN_SFTENA — Configure initial reset for PD_NPU2 by software.
    0=ACTIVE; 1=INACTIVE
  [3] PD_NPU1_INITRSTN_SFTENA — Configure initial reset for PD_NPU1 by software.
    0=ACTIVE; 1=INACTIVE
  [2] PD_NPUTOP_INITRSTN_SFTENA — Configure initial reset for PD_NPUTOP by software.
    0=ACTIVE; 1=INACTIVE
  [1] PD_GPU_INITRSTN_SFTENA — Configure initial reset for PD_PMU1 by software.
    0=ACTIVE; 1=INACTIVE
  [0] PD_PMU1_INITRSTN_SFTENA — Configure initial reset for PD_PMU1 by software.
    0=ACTIVE; 1=INACTIVE
0x822C PMU_BISR_CON11 — Memory repair control register 11
  [31:16] WRITE_ENABLE wo — Write Inactive for lower 16 bits, each bit is individual.
    values as PMU_BISR_CON10.WRITE_ENABLE
  [15] PD_BUS_INITRSTN_SFTENA — Configure initial reset for PD_BUS by software.
    0=ACTIVE; 1=INACTIVE
  [14] PD_DDR23_INITRSTN_SFTENA — Configure initial reset for VD_DDR23 by software.
    0=ACTIVE; 1=INACTIVE
  [13] PD_DDR01_INITRSTN_SFTENA — Configure initial reset for VD_DDR01 by software.
    0=ACTIVE; 1=INACTIVE
  [12] PD_CENTER_INITRSTN_SFTENA — Configure initial reset for PD_CENTER by software.
    0=ACTIVE; 1=INACTIVE
  [11] PD_CRYPTO_INITRSTN_SFTENA — Configure initial reset for PD_CRYPTO by software.
    0=ACTIVE; 1=INACTIVE
  [10] PD_SDMMC_INITRSTN_SFTENA — Configure initial reset for PD_SDMMC by software.
    0=ACTIVE; 1=INACTIVE
  [9] PD_USB_INITRSTN_SFTENA — Configure initial reset for PD_USB by software.
    0=ACTIVE; 1=INACTIVE
  [8] PD_SDIO_INITRSTN_SFTENA — Configure initial reset for PD_SDIO by software.
    0=ACTIVE; 1=INACTIVE
  [7] PD_NVM0_INITRSTN_SFTENA — Configure initial reset for PD_NVM0 by software.
    0=ACTIVE; 1=INACTIVE
  [6] PD_PCIE_INITRSTN_SFTENA — Configure initial reset for PD_PCIE by software.
    0=ACTIVE; 1=INACTIVE
  [5] PD_GMAC_INITRSTN_SFTENA — Configure initial reset for PD_GMAC by software.
    0=ACTIVE; 1=INACTIVE
  [4] PD_PHP_INITRSTN_SFTENA — Configure initial reset for PD_PHP by software.
    0=ACTIVE; 1=INACTIVE
  [3] PD_AUDIO_INITRSTN_SFTENA — Configure initial reset for PD_AUDIO by software.
    0=ACTIVE; 1=INACTIVE
  [2] PD_VO1_INITRSTN_SFTENA — Configure initial reset for PD_VO1 by software.
    0=ACTIVE; 1=INACTIVE
  [1] PD_VO0_INITRSTN_SFTENA — Configure initial reset for PD_VO0 by software.
    0=ACTIVE; 1=INACTIVE
  [0] PD_VOP_INITRSTN_SFTENA — Configure initial reset for PD_VOP by software.
    0=ACTIVE; 1=INACTIVE
0x8230 PMU_BISR_CON12 — Memory repair control register 12
  [all] fields
    0=ACTIVE; 1=INACTIVE
  [15] PD_VOPESMART_INITRSTN_SFTENA — Configure initial reset for PD_VOPESMART by software.
  [14] PD_VOPDSC4K_INITRSTN_SFTENA — Configure initial reset for PD_VOPDSC4K by software.
  [13] PD_VOPDSC8K_INITRSTN_SFTENA — Configure initial reset for PD_VOPDSC8K by software.
  [n+9] PD_VOPCLUSTER{n}_INITRSTN_SFTENA (n=0..3) — Configure initial reset for PD_VOPCLUSTER{n} by software.
  [8-n] PD_CPU{n}_INITRSTN_SFTENA (n=0..7) — Configure initial reset for PD_CPU{n} by software.
  [0] PD_DSU_INITRSTN_SFTENA — Configure initial reset for PD_DSU by software.
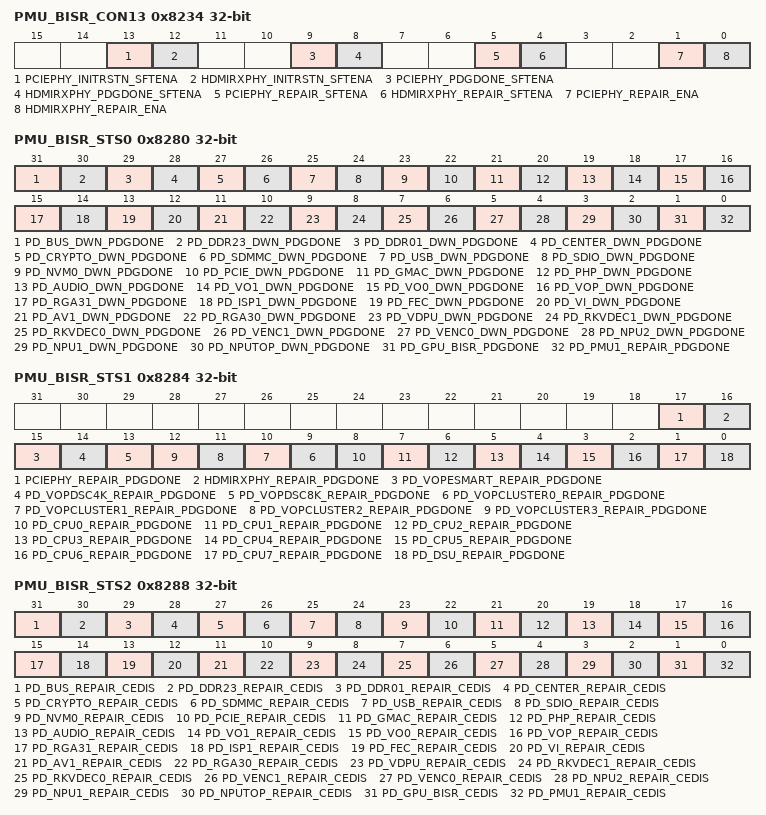
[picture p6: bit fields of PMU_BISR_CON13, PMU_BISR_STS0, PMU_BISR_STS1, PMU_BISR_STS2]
0x8234 PMU_BISR_CON13 — Memory repair control register 13
  [13] PCIEPHY_INITRSTN_SFTENA — Configure repair initial reset for PCIEPHY by software.
    0=ACTIVE; 1=INACTIVE
  [12] HDMIRXPHY_INITRSTN_SFTENA — Configure repair initial reset for HDMIRXPHY by software.
    0=ACTIVE; 1=INACTIVE
  [9] PCIEPHY_PDGDONE_SFTENA — Configure repair done for PCIEPHY by software.
    0=INACTIVE; 1=ACTIVE
  [8] HDMIRXPHY_PDGDONE_SFTENA — Configure repair done for HDMIRXPHY by software.
    0=INACTIVE; 1=ACTIVE
  [5] PCIEPHY_REPAIR_SFTENA — Enable memory repair for PCIEPHY by software.
    0=DISABLE; 1=ENABLE
  [4] HDMIRXPHY_REPAIR_SFTENA — Enable memory repair for HDMIRXPHY by software.
    0=DISABLE; 1=ENABLE
  [1] PCIEPHY_REPAIR_ENA — Enable memory repair for PCIEPHY by hardware.
    0=DISABLE; 1=ENABLE
  [0] HDMIRXPHY_REPAIR_ENA — Enable memory repair for HDMIRXPHY by hardware.
    0=DISABLE; 1=ENABLE
0x8238 PMU_BISR_CON14 — Memory repair control register 14
  [31:0] BISR_TIMEOUT_CNT — BISR timeout count for PDGDone. Number of repair clock used by counter logic.
0x8280 PMU_BISR_STS0 — Memory repair status register 0
  [all] fields
    0=NOT_COMPLETE (Repair not complete); 1=COMPLETE (Repair complete)
  [31] PD_BUS_DWN_PDGDONE ro — PDGDone status for PD_BUS repair.
  [30] PD_DDR23_DWN_PDGDONE ro — PDGDone status for VD_DDR23 repair.
  [29] PD_DDR01_DWN_PDGDONE ro — PDGDone status for VD_DDR01 repair.
  [28] PD_CENTER_DWN_PDGDONE ro — PDGDone status for PD_CENTER repair.
  [27] PD_CRYPTO_DWN_PDGDONE ro — PDGDone status for PD_CRYPTO repair.
  [26] PD_SDMMC_DWN_PDGDONE ro — PDGDone status for PD_SDMMC repair.
  [25] PD_USB_DWN_PDGDONE ro — PDGDone status for PD_USB repair.
  [24] PD_SDIO_DWN_PDGDONE ro — PDGDone status for PD_SDIO repair.
  [23] PD_NVM0_DWN_PDGDONE ro — PDGDone status for PD_NVM0 repair.
  [22] PD_PCIE_DWN_PDGDONE ro — PDGDone status for PD_PCIE repair.
  [21] PD_GMAC_DWN_PDGDONE ro — PDGDone status for PD_GMAC repair.
  [20] PD_PHP_DWN_PDGDONE ro — PDGDone status for PD_PHP repair.
  [19] PD_AUDIO_DWN_PDGDONE ro — PDGDone status for PD_AUDIO repair.
  [18] PD_VO1_DWN_PDGDONE ro — PDGDone status for PD_VO1 repair.
  [17] PD_VO0_DWN_PDGDONE ro — PDGDone status for PD_VO0 repair.
  [16] PD_VOP_DWN_PDGDONE ro — PDGDone status for PD_VOP repair.
  [15] PD_RGA31_DWN_PDGDONE ro — PDGDone status for PD_RGA31 repair.
  [14] PD_ISP1_DWN_PDGDONE ro — PDGDone status for PD_ISP1 repair.
  [13] PD_FEC_DWN_PDGDONE ro — PDGDone status for PD_FEC repair.
  [12] PD_VI_DWN_PDGDONE ro — PDGDone status for PD_VI repair.
  [11] PD_AV1_DWN_PDGDONE ro — PDGDone status for PD_AV1 repair.
  [10] PD_RGA30_DWN_PDGDONE ro — PDGDone status for PD_RGA30 repair.
  [9] PD_VDPU_DWN_PDGDONE ro — PDGDone status for PD_VDPU repair.
  [8] PD_RKVDEC1_DWN_PDGDONE ro — PDGDone status for PD_RKVDEC1 repair.
  [7] PD_RKVDEC0_DWN_PDGDONE ro — PDGDone status for PD_RKVDEC0 repair.
  [6] PD_VENC1_DWN_PDGDONE ro — PDGDone status for PD_VENC1 repair.
  [5] PD_VENC0_DWN_PDGDONE ro — PDGDone status for PD_VENC0 repair.
  [4] PD_NPU2_DWN_PDGDONE ro — PDGDone status for PD_NPU2 repair.
  [3] PD_NPU1_DWN_PDGDONE ro — PDGDone status for PD_NPU1 repair.
  [2] PD_NPUTOP_DWN_PDGDONE ro — PDGDone status for PD_NPUTOP repair.
  [1] PD_GPU_BISR_PDGDONE ro — PDGDone status for VD_GPU repair.
  [0] PD_PMU1_REPAIR_PDGDONE ro — PDGDone status for PD_PMU1 repair.
0x8284 PMU_BISR_STS1 — Memory repair status register 1
  [all] fields
    values as the fields of PMU_BISR_STS0
  [17] PCIEPHY_REPAIR_PDGDONE ro — PDGDone status for PCIEPHY repair.
  [16] HDMIRXPHY_REPAIR_PDGDONE ro — PDGDone status for HDMIRXPHY repair.
  [15] PD_VOPESMART_REPAIR_PDGDONE ro — PDGDone status for PD_VOPESMAKRT repair.
  [14] PD_VOPDSC4K_REPAIR_PDGDONE ro — PDGDone status for PD_VOPDSC4K repair.
  [13] PD_VOPDSC8K_REPAIR_PDGDONE ro — PDGDone status for PD_VOPDSC8K repair.
  [n+9] PD_VOPCLUSTER{n}_REPAIR_PDGDONE ro (n=0..3) — PDGDone status for PD_VOPCLUSTER{n} repair.
  [8] PD_CPU0_REPAIR_PDGDONE ro — PDGDone status for PD_CPU0 repair.
  [7] PD_CPU1_REPAIR_PDGDONE ro — PDGDone status for PD_CPU1 repair.
  [6] PD_CPU2_REPAIR_PDGDONE ro — PDGDone status for PD_CPU3 repair.
  [8-n] PD_CPU{n}_REPAIR_PDGDONE ro (n=3..7) — PDGDone status for PD_CPU{n} repair.
  [0] PD_DSU_REPAIR_PDGDONE ro — PDGDone status for PD_DSU repair.
0x8288 PMU_BISR_STS2 — Memory repair status register 2
  [all] fields
    0=READY (Repair ready); 1=BUSY (Repair busy)
  [31] PD_BUS_REPAIR_CEDIS ro — CEDis status for PD_BUS repair.
  [30] PD_DDR23_REPAIR_CEDIS ro — CEDis status for VD_DDR23 repair.
  [29] PD_DDR01_REPAIR_CEDIS ro — CEDis status for VD_DDR01 repair.
  [28] PD_CENTER_REPAIR_CEDIS ro — CEDis status for PD_CENTER repair.
  [27] PD_CRYPTO_REPAIR_CEDIS ro — CEDis status for PD_CRYPTO repair.
  [26] PD_SDMMC_REPAIR_CEDIS ro — CEDis status for PD_SDMMC repair.
  [25] PD_USB_REPAIR_CEDIS ro — CEDis status for PD_USB repair.
  [24] PD_SDIO_REPAIR_CEDIS ro — CEDis status for PD_SDIO repair.
  [23] PD_NVM0_REPAIR_CEDIS ro — CEDis status for PD_NVM0 repair.
  [22] PD_PCIE_REPAIR_CEDIS ro — CEDis status for PD_PCIE repair.
  [21] PD_GMAC_REPAIR_CEDIS ro — CEDis status for PD_GMAC repair.
  [20] PD_PHP_REPAIR_CEDIS ro — CEDis status for PD_PHP repair.
  [19] PD_AUDIO_REPAIR_CEDIS ro — CEDis status for PD_AUDIO repair.
  [18] PD_VO1_REPAIR_CEDIS ro — CEDis status for PD_VO1 repair.
  [17] PD_VO0_REPAIR_CEDIS ro — CEDis status for PD_VO0 repair.
  [16] PD_VOP_REPAIR_CEDIS ro — CEDis status for PD_VOP repair.
  [15] PD_RGA31_REPAIR_CEDIS ro — CEDis status for PD_RGA31 repair.
  [14] PD_ISP1_REPAIR_CEDIS ro — CEDis status for PD_ISP1 repair.
  [13] PD_FEC_REPAIR_CEDIS ro — CEDis status for PD_FEC repair.
  [12] PD_VI_REPAIR_CEDIS ro — CEDis status for PD_VI repair.
  [11] PD_AV1_REPAIR_CEDIS ro — CEDis status for PD_AV1 repair.
  [10] PD_RGA30_REPAIR_CEDIS ro — CEDis status for PD_RGA30 repair.
  [9] PD_VDPU_REPAIR_CEDIS ro — CEDis status for PD_VDPU repair.
  [8] PD_RKVDEC1_REPAIR_CEDIS ro — CEDis status for PD_RKVDEC1 repair.
  [7] PD_RKVDEC0_REPAIR_CEDIS ro — CEDis status for PD_RKVDEC0 repair.
  [6] PD_VENC1_REPAIR_CEDIS ro — CEDis status for PD_VENC1 repair.
  [5] PD_VENC0_REPAIR_CEDIS ro — CEDis status for PD_VENC0 repair.
  [4] PD_NPU2_REPAIR_CEDIS ro — CEDis status for PD_NPU2 repair.
  [3] PD_NPU1_REPAIR_CEDIS ro — CEDis status for PD_NPU1 repair.
  [2] PD_NPUTOP_REPAIR_CEDIS ro — CEDis status for PD_NPUTOP repair.
  [1] PD_GPU_BISR_CEDIS ro — CEDis status for VD_GPU repair.
  [0] PD_PMU1_REPAIR_CEDIS ro — CEDis status for PD_PMU1 repair.
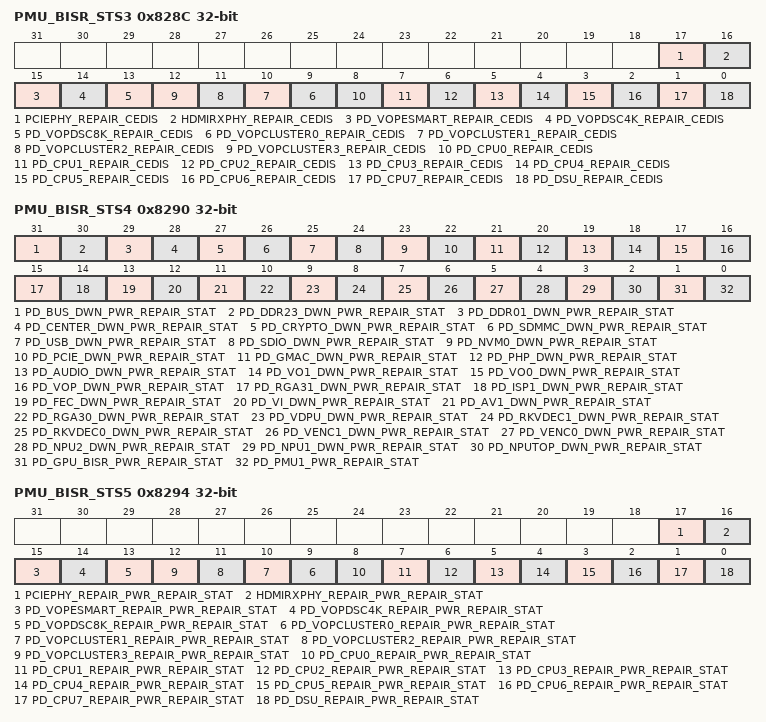
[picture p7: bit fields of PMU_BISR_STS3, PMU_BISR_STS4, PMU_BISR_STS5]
0x828C PMU_BISR_STS3 — Memory repair status register 3
  [all] fields
    0=READY (Repair ready); 1=BUSY (Repair busy)
  [17] PCIEPHY_REPAIR_CEDIS ro — CEDis status for PCIEPHY repair.
  [16] HDMIRXPHY_REPAIR_CEDIS ro — CEDis status for HDMIRXPHY repair.
  [15] PD_VOPESMART_REPAIR_CEDIS ro — CEDis status for PD_VOPESMAKRT repair.
  [14] PD_VOPDSC4K_REPAIR_CEDIS ro — CEDis status for PD_VOPDSC4K repair.
  [13] PD_VOPDSC8K_REPAIR_CEDIS ro — CEDis status for PD_VOPDSC8K repair.
  [n+9] PD_VOPCLUSTER{n}_REPAIR_CEDIS ro (n=0..3) — CEDis status for PD_VOPCLUSTER{n} repair.
  [8] PD_CPU0_REPAIR_CEDIS ro — CEDis status for PD_CPU0 repair.
  [7] PD_CPU1_REPAIR_CEDIS ro — CEDis status for PD_CPU1 repair.
  [6] PD_CPU2_REPAIR_CEDIS ro — CEDis status for PD_CPU3 repair.
  [8-n] PD_CPU{n}_REPAIR_CEDIS ro (n=3..7) — CEDis status for PD_CPU{n} repair.
  [0] PD_DSU_REPAIR_CEDIS ro — CEDis status for PD_DSU repair.
0x8290 PMU_BISR_STS4 — Memory repair status register 4
  [all] fields
    0=DOWN_OR_INCOMPLETE (Power down or repair not complete); 1=UP_AND_COMPLETE (Power up and repair complete)
  [31] PD_BUS_DWN_PWR_REPAIR_STAT ro — Power and repair status for PD_BUS repair.
  [30] PD_DDR23_DWN_PWR_REPAIR_STAT ro — Power and repair status for VD_DDR23 repair.
  [29] PD_DDR01_DWN_PWR_REPAIR_STAT ro — Power and repair status for VD_DDR01 repair.
  [28] PD_CENTER_DWN_PWR_REPAIR_STAT ro — Power and repair status for PD_CENTER repair.
  [27] PD_CRYPTO_DWN_PWR_REPAIR_STAT ro — Power and repair status for PD_CRYPTO repair.
  [26] PD_SDMMC_DWN_PWR_REPAIR_STAT ro — Power and repair status for PD_SDMMC repair.
  [25] PD_USB_DWN_PWR_REPAIR_STAT ro — Power and repair status for PD_USB repair.
  [24] PD_SDIO_DWN_PWR_REPAIR_STAT ro — Power and repair status for PD_SDIO repair.
  [23] PD_NVM0_DWN_PWR_REPAIR_STAT ro — Power and repair status for PD_NVM0 repair.
  [22] PD_PCIE_DWN_PWR_REPAIR_STAT ro — Power and repair status for PD_PCIE repair.
  [21] PD_GMAC_DWN_PWR_REPAIR_STAT ro — Power and repair status for PD_GMAC repair.
  [20] PD_PHP_DWN_PWR_REPAIR_STAT ro — Power and repair status for PD_PHP repair.
  [19] PD_AUDIO_DWN_PWR_REPAIR_STAT ro — Power and repair status for PD_AUDIO repair.
  [18] PD_VO1_DWN_PWR_REPAIR_STAT ro — Power and repair status for PD_VO1 repair.
  [17] PD_VO0_DWN_PWR_REPAIR_STAT ro — Power and repair status for PD_VO0 repair.
  [16] PD_VOP_DWN_PWR_REPAIR_STAT ro — Power and repair status for PD_VOP repair.
  [15] PD_RGA31_DWN_PWR_REPAIR_STAT ro — Power and repair status for PD_RGA31 repair.
  [14] PD_ISP1_DWN_PWR_REPAIR_STAT ro — Power and repair status for PD_ISP1 repair.
  [13] PD_FEC_DWN_PWR_REPAIR_STAT ro — Power and repair status for PD_FEC repair.
  [12] PD_VI_DWN_PWR_REPAIR_STAT ro — Power and repair status for PD_VI repair.
  [11] PD_AV1_DWN_PWR_REPAIR_STAT ro — Power and repair status for PD_AV1 repair.
  [10] PD_RGA30_DWN_PWR_REPAIR_STAT ro — Power and repair status for PD_RGA30 repair.
  [9] PD_VDPU_DWN_PWR_REPAIR_STAT ro — Power and repair status for PD_VDPU repair.
  [8] PD_RKVDEC1_DWN_PWR_REPAIR_STAT ro — Power and repair status for PD_RKVDEC1 repair.
  [7] PD_RKVDEC0_DWN_PWR_REPAIR_STAT ro — Power and repair status for PD_RKVDEC0 repair.
  [6] PD_VENC1_DWN_PWR_REPAIR_STAT ro — Power and repair status for PD_VENC1 repair.
  [5] PD_VENC0_DWN_PWR_REPAIR_STAT ro — Power and repair status for PD_VENC0 repair.
  [4] PD_NPU2_DWN_PWR_REPAIR_STAT ro — Power and repair status for PD_NPU2 repair.
  [3] PD_NPU1_DWN_PWR_REPAIR_STAT ro — Power and repair status for PD_NPU1 repair.
  [2] PD_NPUTOP_DWN_PWR_REPAIR_STAT ro — Power and repair status for PD_NPUTOP repair.
  [1] PD_GPU_BISR_PWR_REPAIR_STAT ro — Power and repair status for VD_GPU repair.
  [0] PD_PMU1_PWR_REPAIR_STAT ro — Power and repair status for PD_PMU1.
0x8294 PMU_BISR_STS5 — Memory repair status register 5
  [all] fields
    values as the fields of PMU_BISR_STS4
  [17] PCIEPHY_REPAIR_PWR_REPAIR_STAT ro — Power and repair status for PCIEPHY repair.
  [16] HDMIRXPHY_REPAIR_PWR_REPAIR_STAT ro — Power and repair status for HDMIRXPHY repair.
  [15] PD_VOPESMART_REPAIR_PWR_REPAIR_STAT ro — Power and repair status for PD_VOPESMAKRT repair.
  [14] PD_VOPDSC4K_REPAIR_PWR_REPAIR_STAT ro — Power and repair status for PD_VOPDSC4K repair.
  [13] PD_VOPDSC8K_REPAIR_PWR_REPAIR_STAT ro — Power and repair status for PD_VOPDSC8K repair.
  [n+9] PD_VOPCLUSTER{n}_REPAIR_PWR_REPAIR_STAT ro (n=0..3) — Power and repair status for PD_VOPCLUSTER{n} repair.
  [8] PD_CPU0_REPAIR_PWR_REPAIR_STAT ro — Power and repair status for PD_CPU0 repair.
  [7] PD_CPU1_REPAIR_PWR_REPAIR_STAT ro — Power and repair status for PD_CPU1 repair.
  [6] PD_CPU2_REPAIR_PWR_REPAIR_STAT ro — Power and repair status for PD_CPU3 repair.
  [8-n] PD_CPU{n}_REPAIR_PWR_REPAIR_STAT ro (n=3..7) — Power and repair status for PD_CPU{n} repair.
  [0] PD_DSU_REPAIR_PWR_REPAIR_STAT ro — Power and repair status for PD_DSU repair.
